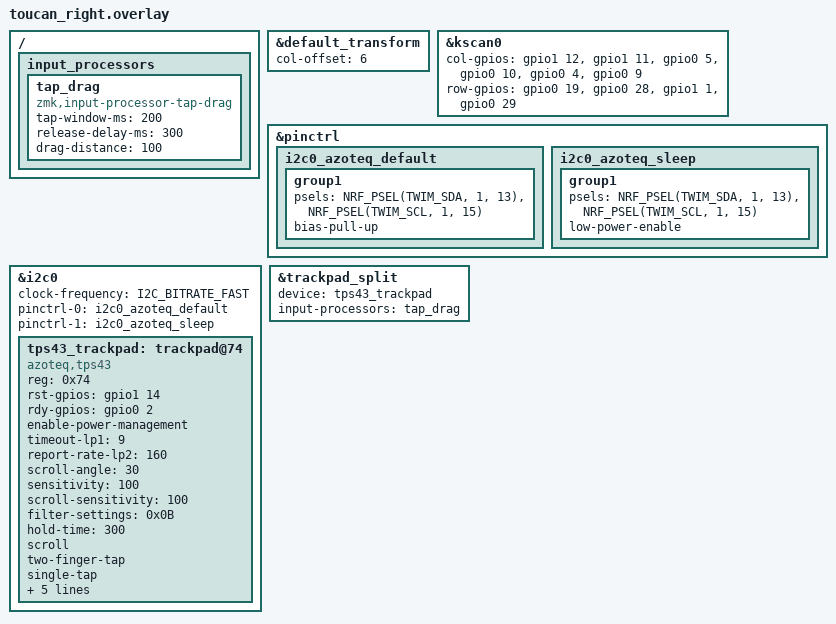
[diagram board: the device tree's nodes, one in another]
#include "toucan.dtsi"

&default_transform {
    col-offset = <6>;
};

&kscan0 {
    col-gpios
    = <&gpio1 12 GPIO_ACTIVE_HIGH>
    , <&gpio1 11 GPIO_ACTIVE_HIGH>
    , <&gpio0 5 GPIO_ACTIVE_HIGH>
    , <&gpio0 10 GPIO_ACTIVE_HIGH>
    , <&gpio0 4 GPIO_ACTIVE_HIGH>
    , <&gpio0 9 GPIO_ACTIVE_HIGH>
    ;

    row-gpios
    = <&gpio0 19 (GPIO_ACTIVE_HIGH | GPIO_PULL_DOWN)>
    , <&gpio0 28 (GPIO_ACTIVE_HIGH | GPIO_PULL_DOWN)>
    , <&gpio1 1 (GPIO_ACTIVE_HIGH | GPIO_PULL_DOWN)>
    , <&gpio0 29 (GPIO_ACTIVE_HIGH | GPIO_PULL_DOWN)>
    ;
};

&pinctrl {
    i2c0_azoteq_default: i2c0_azoteq_default {
        group1 {
            psels = <NRF_PSEL(TWIM_SDA, 1, 13)>,
                    <NRF_PSEL(TWIM_SCL, 1, 15)>;
            bias-pull-up;
        };
    };

    i2c0_azoteq_sleep: i2c0_azoteq_sleep {
        group1 {
            psels = <NRF_PSEL(TWIM_SDA, 1, 13)>,
                    <NRF_PSEL(TWIM_SCL, 1, 15)>;
            low-power-enable;
        };
    };
};

&i2c0 {
   status = "okay";
    clock-frequency = <I2C_BITRATE_FAST>;
    pinctrl-0 = <&i2c0_azoteq_default>;
    pinctrl-1 = <&i2c0_azoteq_sleep>;
    pinctrl-names = "default", "sleep";

    tps43_trackpad: trackpad@74 {
        compatible = "azoteq,tps43";
        reg = <0x74>;
        status = "okay";

        rst-gpios = <&gpio1 14 GPIO_ACTIVE_HIGH>;
        rdy-gpios = <&gpio0 2 GPIO_ACTIVE_HIGH>;

        enable-power-management;
        // idle-sleep; // provides maximal power savings but when ZMK is idle (i.e. you haven't used keyboard in 30secs) the touchpad will not work.  not recommended.

        // Wake latency vs. power: the trackpad walks itself down ACTIVE ->
        // IDLE -> LP1 -> LP2 on its own timers. In LP2 it only *scans* for a
        // finger once per report period, and it needs a couple of scans (plus
        // an ATI re-tune) before it starts reporting movement. With LP2 at
        // 640ms that turned into multiple seconds of dead cursor the first
        // time you touched the pad after typing for a while, and the stock
        // TIMEOUT_LP1 (20s) meant it reached LP2 almost immediately.
        //
        // So: stay in LP1 for 180s (9 * 20s units) and keep LP2 scanning at
        // the driver default 160ms. Costs roughly 120uA more than 640ms LP2,
        // which is negligible next to the ~2mA the board draws anyway.
        timeout-lp1 = <9>;
        report-rate-lp2 = <160>;
        scroll-angle = <30>; // The default angle (about 47 deg) is too big on toucan2 I think

        // Cursor tracking speed. 100 is the driver's "normal" baseline and the
        // curve shaping now lives in the pointer_accel input processor (see
        // toucan.dtsi) rather than in this single flat multiplier. Raising this
        // scales the whole acceleration curve up; to change only the slow or
        // only the fast end, adjust min-factor / max-factor instead.
        sensitivity = <100>;
        scroll-sensitivity = <100>;

        filter-settings=<0x0B>;

        // Press-and-hold-to-drag ("click and hold"). The driver's press-and-hold
        // gesture holds the left button down once a finger has been held (within
        // tap-distance) for longer than hold-time, then drags with movement and
        // releases on lift -- see the TPS43_PRESS_AND_HOLD handling in the tps43
        // driver. Dropped 500 -> 300ms so the drag engages promptly after a
        // sharp touch instead of feeling like a long press. Still comfortably
        // above the (unset, hardware-default ~150ms) tap-time, so a quick tap is
        // still a plain click and only a deliberate hold starts a drag. Lower
        // for a snappier hold; raise if resting a finger starts unwanted drags.
        //
        // The quicker way to drag is double-tap-and-hold (macOS's "tap to
        // drag"): tap, then put the finger straight back down. That is not a
        // hardware gesture, so it is built on top of the driver's taps by the
        // tap_drag processor below. While a tap-drag holds the button, this
        // gesture's own press is absorbed rather than sent twice.
        hold-time = <300>;

        // zoom; // Disabled: pinch-to-zoom (Cmd+/Cmd-) kept firing accidentally
        // during normal two-finger scrolling/movement. Not present -> the
        // driver never detects/reports the gesture at all (see the tps43
        // driver's TPS43_ZOOM handling, gated on config->zoom).
        scroll;
        two-finger-tap;
        single-tap;
        press-and-hold;
        //swipes;
        three-finger-swipe;
        // Turned down from 1200 so swipe_arbiter (see toucan.dtsi) receives a
        // stream of direction samples to pick the dominant axis from. The
        // arbiter enforces one actuation per gesture, so this no longer needs
        // to suppress repeats on its own. Restore 1200 if the arbiter is removed.
        three-finger-swipe-throttle-ms = <40>;
        switch-xy;
        invert-scroll-y;

    };
};

/ {
    input_processors {
        // Double-tap-and-hold to drag, like macOS's "tap to drag" (without
        // drag lock): tap, then put the finger straight back down, and the left
        // button stays held while it is down. A second quick tap is still a
        // double click. See src/input_processor_tap_drag.c.
        //
        // It runs here on the right half, on the raw driver events and before
        // they cross the split link, so its timing is measured at the source
        // and it works the same in standalone and dongle mode. Only this half
        // needs reflashing to change it; the rotation variants on the central
        // are unaffected.
        //
        //   - tap-window-ms: how soon after a tap the finger must return to start
        //     a drag. A plain tap's release also waits this long, since the
        //     press has to stay down in case a drag follows. Raise it if the
        //     double-tap is hard to land, lower it for snappier single clicks.
        //   - release-delay-ms: lifting mid-drag keeps holding the button this
        //     long so the finger can be repositioned on the small pad. A touch
        //     inside it carries on the same drag, and a tap inside it drops at
        //     once. 0 releases the moment the finger lifts.
        //   - drag-distance: travel after which the held tap counts as a real
        //     drag, so a tap during the release delay drops it instead of
        //     adding a double click.
        tap_drag: tap_drag {
            compatible = "zmk,input-processor-tap-drag";
            #input-processor-cells = <0>;
            tap-window-ms = <200>;
            release-delay-ms = <300>;
            drag-distance = <100>;
        };
    };
};

&trackpad_split {
    device = <&tps43_trackpad>;
    input-processors = <&tap_drag>;
};
